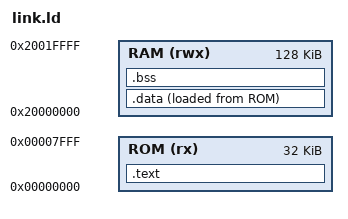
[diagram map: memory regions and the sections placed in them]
OUTPUT_ARCH(riscv)
ENTRY(_start)
MEMORY { ROM (rx) : ORIGIN = 0, LENGTH = 32K
         RAM (rwx) : ORIGIN = 0x20000000, LENGTH = 128K }
SECTIONS {
 .text : { KEEP(*(.text.start)) *(.text*) *(.rodata*) . = ALIGN(4); } > ROM
 .data : { _data_start = .; *(.data*) *(.sdata*) . = ALIGN(4); _data_end = .; } > RAM AT> ROM
 _data_load = LOADADDR(.data);
 .bss (NOLOAD) : { _bss_start = .; *(.bss*) *(.sbss*) *(COMMON) . = ALIGN(4); _bss_end = .; } > RAM
 _stack_top = ORIGIN(RAM)+LENGTH(RAM)-16;
 ASSERT(_bss_end < _stack_top - 4096, "RAM overflow / stack reserve")
 /DISCARD/ : { *(.comment*) *(.eh_frame*) *(.riscv.attributes*) }
}
